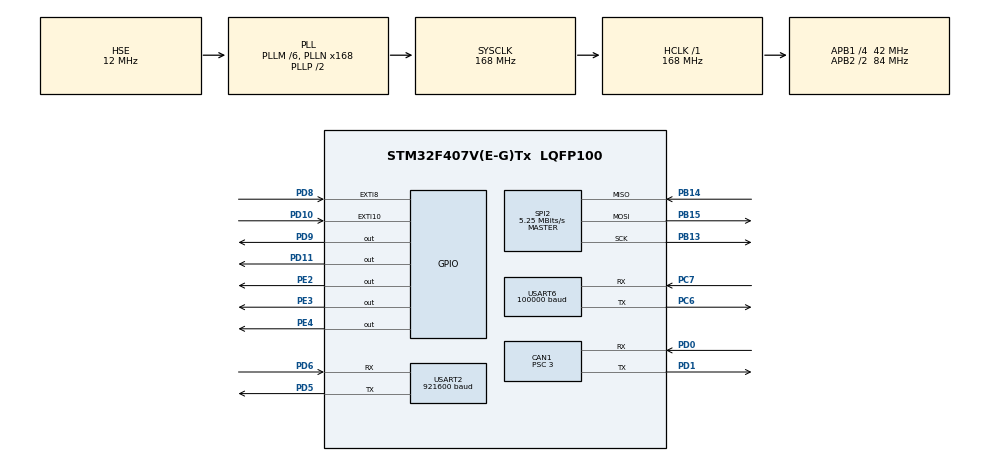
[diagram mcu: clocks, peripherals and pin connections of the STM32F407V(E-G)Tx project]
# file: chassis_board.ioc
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CAN1.BS1=CAN_BS1_10TQ
CAN1.BS2=CAN_BS2_3TQ
CAN1.CalculateBaudRate=1000000
CAN1.CalculateTimeBit=1000
CAN1.CalculateTimeQuantum=71.42857142857143
CAN1.Prescaler=3
Dma.Request0=USART6_RX
Dma.Request1=USART2_TX
Dma.Request2=USART2_RX
Dma.USART2_RX.2.Direction=DMA_PERIPH_TO_MEMORY
Dma.USART2_RX.2.FIFOMode=DMA_FIFOMODE_DISABLE
Dma.USART2_RX.2.Instance=DMA1_Stream5
Dma.USART2_RX.2.MemDataAlignment=DMA_MDATAALIGN_BYTE
Dma.USART2_RX.2.MemInc=DMA_MINC_ENABLE
Dma.USART2_RX.2.Mode=DMA_NORMAL
Dma.USART2_RX.2.PeriphDataAlignment=DMA_PDATAALIGN_BYTE
Dma.USART2_RX.2.PeriphInc=DMA_PINC_DISABLE
Dma.USART2_RX.2.Priority=DMA_PRIORITY_LOW
Dma.USART2_TX.1.Direction=DMA_MEMORY_TO_PERIPH
Dma.USART2_TX.1.FIFOMode=DMA_FIFOMODE_DISABLE
Dma.USART2_TX.1.Instance=DMA1_Stream6
Dma.USART2_TX.1.MemDataAlignment=DMA_MDATAALIGN_BYTE
Dma.USART2_TX.1.MemInc=DMA_MINC_ENABLE
Dma.USART2_TX.1.Mode=DMA_NORMAL
Dma.USART2_TX.1.PeriphDataAlignment=DMA_PDATAALIGN_BYTE
Dma.USART2_TX.1.PeriphInc=DMA_PINC_DISABLE
Dma.USART2_TX.1.Priority=DMA_PRIORITY_LOW
Dma.USART6_RX.0.Direction=DMA_PERIPH_TO_MEMORY
Dma.USART6_RX.0.FIFOMode=DMA_FIFOMODE_DISABLE
Dma.USART6_RX.0.Instance=DMA2_Stream1
Dma.USART6_RX.0.MemDataAlignment=DMA_MDATAALIGN_BYTE
Dma.USART6_RX.0.MemInc=DMA_MINC_ENABLE
Dma.USART6_RX.0.Mode=DMA_NORMAL
Dma.USART6_RX.0.PeriphDataAlignment=DMA_PDATAALIGN_BYTE
Dma.USART6_RX.0.PeriphInc=DMA_PINC_DISABLE
Dma.USART6_RX.0.Priority=DMA_PRIORITY_LOW
FREERTOS.Tasks01=defaultTask,8,128,StartDefaultTask,Default,NULL,Dynamic,NULL,NULL;run,40,128,runTask,As external,NULL,Dynamic,NULL,NULL;send,32,128,sendTask,As external,NULL,Dynamic,NULL,NULL;blink,24,128,blinkTask,As external,NULL,Dynamic,NULL,NULL;INS,48,128,INSTask,As external,NULL,Dynamic,NULL,NULL
Mcu.Family=STM32F4
Mcu.Name=STM32F407V(E-G)Tx
Mcu.Package=LQFP100
NVIC.CAN1_RX0_IRQn=true\:5\:0\:false\:false\:true\:true\:true\:true\:true
NVIC.CAN1_RX1_IRQn=true\:5\:0\:false\:false\:true\:true\:true\:true\:true
NVIC.DMA1_Stream5_IRQn=true\:5\:0\:false\:false\:true\:true\:false\:true\:true
NVIC.DMA1_Stream6_IRQn=true\:5\:0\:false\:false\:true\:true\:false\:true\:true
NVIC.DMA2_Stream1_IRQn=true\:5\:0\:false\:false\:true\:true\:false\:true\:true
NVIC.PriorityGroup=NVIC_PRIORITYGROUP_4
NVIC.SPI2_IRQn=true\:5\:0\:false\:false\:true\:true\:true\:true\:true
NVIC.TIM1_UP_TIM10_IRQn=true\:15\:0\:false\:false\:true\:false\:false\:true\:true
NVIC.TimeBase=TIM1_UP_TIM10_IRQn
NVIC.TimeBaseIP=TIM1
NVIC.USART2_IRQn=true\:5\:0\:false\:false\:true\:true\:true\:true\:true
NVIC.USART6_IRQn=true\:5\:0\:false\:false\:true\:true\:true\:true\:true
PA13.Mode=Serial_Wire
PA13.Signal=SYS_JTMS-SWDIO
PA14.Mode=Serial_Wire
PA14.Signal=SYS_JTCK-SWCLK
PB13.Mode=Full_Duplex_Master
PB13.Signal=SPI2_SCK
PB14.Mode=Full_Duplex_Master
PB14.Signal=SPI2_MISO
PB15.Mode=Full_Duplex_Master
PB15.Signal=SPI2_MOSI
PC6.Mode=Asynchronous
PC6.Signal=USART6_TX
PC7.Mode=Asynchronous
PC7.Signal=USART6_RX
PD0.Mode=CAN_Activate
PD0.Signal=CAN1_RX
PD1.Mode=CAN_Activate
PD1.Signal=CAN1_TX
PD10.Signal=GPXTI10
PD11.GPIO_Speed=GPIO_SPEED_FREQ_VERY_HIGH
PD11.Signal=GPIO_Output
PD5.Mode=Asynchronous
PD5.Signal=USART2_TX
PD6.Mode=Asynchronous
PD6.Signal=USART2_RX
PD8.Signal=GPXTI8
PD9.GPIO_Speed=GPIO_SPEED_FREQ_VERY_HIGH
PD9.Signal=GPIO_Output
PE2.PinState=GPIO_PIN_SET
PE2.Signal=GPIO_Output
PE3.PinState=GPIO_PIN_SET
PE3.Signal=GPIO_Output
PE4.PinState=GPIO_PIN_SET
PE4.Signal=GPIO_Output
PH0-OSC_IN.Mode=HSE-External-Oscillator
PH0-OSC_IN.Signal=RCC_OSC_IN
PH1-OSC_OUT.Mode=HSE-External-Oscillator
PH1-OSC_OUT.Signal=RCC_OSC_OUT
ProjectManager.HeapSize=0x200
ProjectManager.StackSize=0x400
ProjectManager.TargetToolchain=CMake
RCC.48MHZClocksFreq_Value=84000000
RCC.AHBFreq_Value=168000000
RCC.APB1CLKDivider=RCC_HCLK_DIV4
RCC.APB1Freq_Value=42000000
RCC.APB1TimFreq_Value=84000000
RCC.APB2CLKDivider=RCC_HCLK_DIV2
RCC.APB2Freq_Value=84000000
RCC.APB2TimFreq_Value=168000000
RCC.CortexFreq_Value=168000000
RCC.HCLKFreq_Value=168000000
RCC.HSE_VALUE=12000000
RCC.HSI_VALUE=16000000
RCC.LSE_VALUE=32768
RCC.PLLM=6
RCC.PLLN=168
RCC.PLLSourceVirtual=RCC_PLLSOURCE_HSE
RCC.SYSCLKFreq_VALUE=168000000
RCC.SYSCLKSource=RCC_SYSCLKSOURCE_PLLCLK
RCC.VCOOutputFreq_Value=336000000
SPI2.BaudRatePrescaler=SPI_BAUDRATEPRESCALER_8
SPI2.CLKPhase=SPI_PHASE_2EDGE
SPI2.CLKPolarity=SPI_POLARITY_HIGH
SPI2.CalculateBaudRate=5.25 MBits/s
SPI2.Direction=SPI_DIRECTION_2LINES
SPI2.Mode=SPI_MODE_MASTER
SPI2.VirtualType=VM_MASTER
USART2.BaudRate=921600
USART2.VirtualMode=VM_ASYNC
USART6.BaudRate=100000
USART6.Mode=MODE_RX
USART6.Parity=PARITY_EVEN
USART6.VirtualMode=VM_ASYNC
USART6.WordLength=WORDLENGTH_9B
VP_FREERTOS_VS_CMSIS_V2.Mode=CMSIS_V2
VP_SYS_VS_tim1.Mode=TIM1
board=custom

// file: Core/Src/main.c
/* USER CODE BEGIN Header */
/**
  ******************************************************************************
  * @file           : main.c
  * @brief          : Main program body
  ******************************************************************************
  * @attention
  *
  * Copyright (c) 2026 STMicroelectronics.
  * All rights reserved.
  *
  * This software is licensed under terms that can be found in the LICENSE file
  * in the root directory of this software component.
  * If no LICENSE file comes with this software, it is provided AS-IS.
  *
  ******************************************************************************
  */
/* USER CODE END Header */
#include "main.h"
#include "cmsis_os.h"
#include "can.h"
#include "dma.h"
#include "spi.h"
#include "usart.h"
#include "gpio.h"

/* USER CODE BEGIN Includes */
#include "run.h"
#include "init.h"
/* USER CODE END Includes */

void SystemClock_Config(void);
void MX_FREERTOS_Init(void);

int main(void)
{

  /* MCU Configuration--------------------------------------------------------*/

  /* Reset of all peripherals, Initializes the Flash interface and the Systick. */
  HAL_Init();

  /* Configure the system clock */
  SystemClock_Config();

  /* Initialize all configured peripherals */
  MX_GPIO_Init();
  MX_DMA_Init();
  MX_CAN1_Init();
  MX_USART2_UART_Init();
  MX_USART6_UART_Init();
  MX_SPI2_Init();
  /* USER CODE BEGIN 2 */
  System_Init();
  /* USER CODE END 2 */

  /* Init scheduler */
  osKernelInitialize();  /* Call init function for freertos objects (in cmsis_os2.c) */
  MX_FREERTOS_Init();

  /* Start scheduler */
  osKernelStart();

  /* We should never get here as control is now taken by the scheduler */

  /* Infinite loop */
  while (1)
  {

  }
}

void SystemClock_Config(void)
{
  RCC_OscInitTypeDef RCC_OscInitStruct = {0};
  RCC_ClkInitTypeDef RCC_ClkInitStruct = {0};

  /** Configure the main internal regulator output voltage
  */
  __HAL_RCC_PWR_CLK_ENABLE();
  __HAL_PWR_VOLTAGESCALING_CONFIG(PWR_REGULATOR_VOLTAGE_SCALE1);

  /** Initializes the RCC Oscillators according to the specified parameters
  * in the RCC_OscInitTypeDef structure.
  */
  RCC_OscInitStruct.OscillatorType = RCC_OSCILLATORTYPE_HSE;
  RCC_OscInitStruct.HSEState = RCC_HSE_ON;
  RCC_OscInitStruct.PLL.PLLState = RCC_PLL_ON;
  RCC_OscInitStruct.PLL.PLLSource = RCC_PLLSOURCE_HSE;
  RCC_OscInitStruct.PLL.PLLM = 6;
  RCC_OscInitStruct.PLL.PLLN = 168;
  RCC_OscInitStruct.PLL.PLLP = RCC_PLLP_DIV2;
  RCC_OscInitStruct.PLL.PLLQ = 4;
  if (HAL_RCC_OscConfig(&RCC_OscInitStruct) != HAL_OK)
  {
    Error_Handler();
  }

  /** Initializes the CPU, AHB and APB buses clocks
  */
  RCC_ClkInitStruct.ClockType = RCC_CLOCKTYPE_HCLK|RCC_CLOCKTYPE_SYSCLK
                              |RCC_CLOCKTYPE_PCLK1|RCC_CLOCKTYPE_PCLK2;
  RCC_ClkInitStruct.SYSCLKSource = RCC_SYSCLKSOURCE_PLLCLK;
  RCC_ClkInitStruct.AHBCLKDivider = RCC_SYSCLK_DIV1;
  RCC_ClkInitStruct.APB1CLKDivider = RCC_HCLK_DIV4;
  RCC_ClkInitStruct.APB2CLKDivider = RCC_HCLK_DIV2;

  if (HAL_RCC_ClockConfig(&RCC_ClkInitStruct, FLASH_LATENCY_5) != HAL_OK)
  {
    Error_Handler();
  }
}

void HAL_TIM_PeriodElapsedCallback(TIM_HandleTypeDef *htim)
{
  if (htim->Instance == TIM1)
  {
    HAL_IncTick();
  }
}

void Error_Handler(void)
{
  __disable_irq();
  while (1)
  {
  }
}

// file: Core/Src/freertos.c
/* USER CODE BEGIN Header */
/**
  ******************************************************************************
  * File Name          : freertos.c
  * Description        : Code for freertos applications
  ******************************************************************************
  * @attention
  *
  * Copyright (c) 2026 STMicroelectronics.
  * All rights reserved.
  *
  * This software is licensed under terms that can be found in the LICENSE file
  * in the root directory of this software component.
  * If no LICENSE file comes with this software, it is provided AS-IS.
  *
  ******************************************************************************
  */
/* USER CODE END Header */

#include "FreeRTOS.h"
#include "task.h"
#include "main.h"
#include "cmsis_os.h"

/* USER CODE BEGIN Variables */
osEventFlagsId_t imu_init_event;
/* USER CODE END Variables */
/* Definitions for defaultTask */
osThreadId_t defaultTaskHandle;
const osThreadAttr_t defaultTask_attributes = {
  .name = "defaultTask",
  .stack_size = 128 * 4,
  .priority = (osPriority_t) osPriorityLow,
};
/* Definitions for run */
osThreadId_t runHandle;
const osThreadAttr_t run_attributes = {
  .name = "run",
  .stack_size = 128 * 4,
  .priority = (osPriority_t) osPriorityHigh,
};
/* Definitions for send */
osThreadId_t sendHandle;
const osThreadAttr_t send_attributes = {
  .name = "send",
  .stack_size = 128 * 4,
  .priority = (osPriority_t) osPriorityAboveNormal,
};
/* Definitions for blink */
osThreadId_t blinkHandle;
const osThreadAttr_t blink_attributes = {
  .name = "blink",
  .stack_size = 128 * 4,
  .priority = (osPriority_t) osPriorityNormal,
};
/* Definitions for INS */
osThreadId_t INSHandle;
const osThreadAttr_t INS_attributes = {
  .name = "INS",
  .stack_size = 128 * 4,
  .priority = (osPriority_t) osPriorityRealtime,
};

void StartDefaultTask(void *argument);
extern void runTask(void *argument);
extern void sendTask(void *argument);
extern void blinkTask(void *argument);
extern void INSTask(void *argument);

void MX_FREERTOS_Init(void); /* (MISRA C 2004 rule 8.1) */

void MX_FREERTOS_Init(void) {

  /* Create the thread(s) */
  /* creation of defaultTask */
  defaultTaskHandle = osThreadNew(StartDefaultTask, NULL, &defaultTask_attributes);

  /* creation of run */
  runHandle = osThreadNew(runTask, NULL, &run_attributes);

  /* creation of send */
  sendHandle = osThreadNew(sendTask, NULL, &send_attributes);

  /* creation of blink */
  blinkHandle = osThreadNew(blinkTask, NULL, &blink_attributes);

  /* creation of INS */
  INSHandle = osThreadNew(INSTask, NULL, &INS_attributes);

  /* USER CODE BEGIN RTOS_EVENTS */
  /* add events, ... */
  imu_init_event = osEventFlagsNew(NULL);
  /* USER CODE END RTOS_EVENTS */

}

void StartDefaultTask(void *argument)
{
  for(;;)
  {
    osDelay(1);
  }
}
